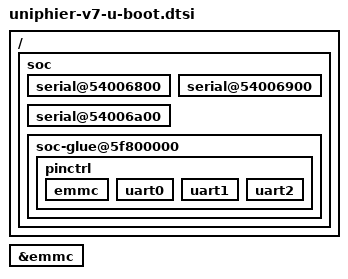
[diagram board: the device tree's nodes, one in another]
/ {
	soc {
		u-boot,dm-all;

		serial@54006800 {
			u-boot,dm-all;
		};

		serial@54006900 {
			u-boot,dm-all;
		};

		serial@54006a00 {
			u-boot,dm-all;
		};

		soc-glue@5f800000 {
			u-boot,dm-all;

			pinctrl {
				u-boot,dm-all;

				emmc {
					u-boot,dm-all;
				};

				uart0 {
					u-boot,dm-all;
				};

				uart1 {
					u-boot,dm-all;
				};

				uart2 {
					u-boot,dm-all;
				};
			};
		};
	};
};

&emmc {
	u-boot,dm-all;
};
